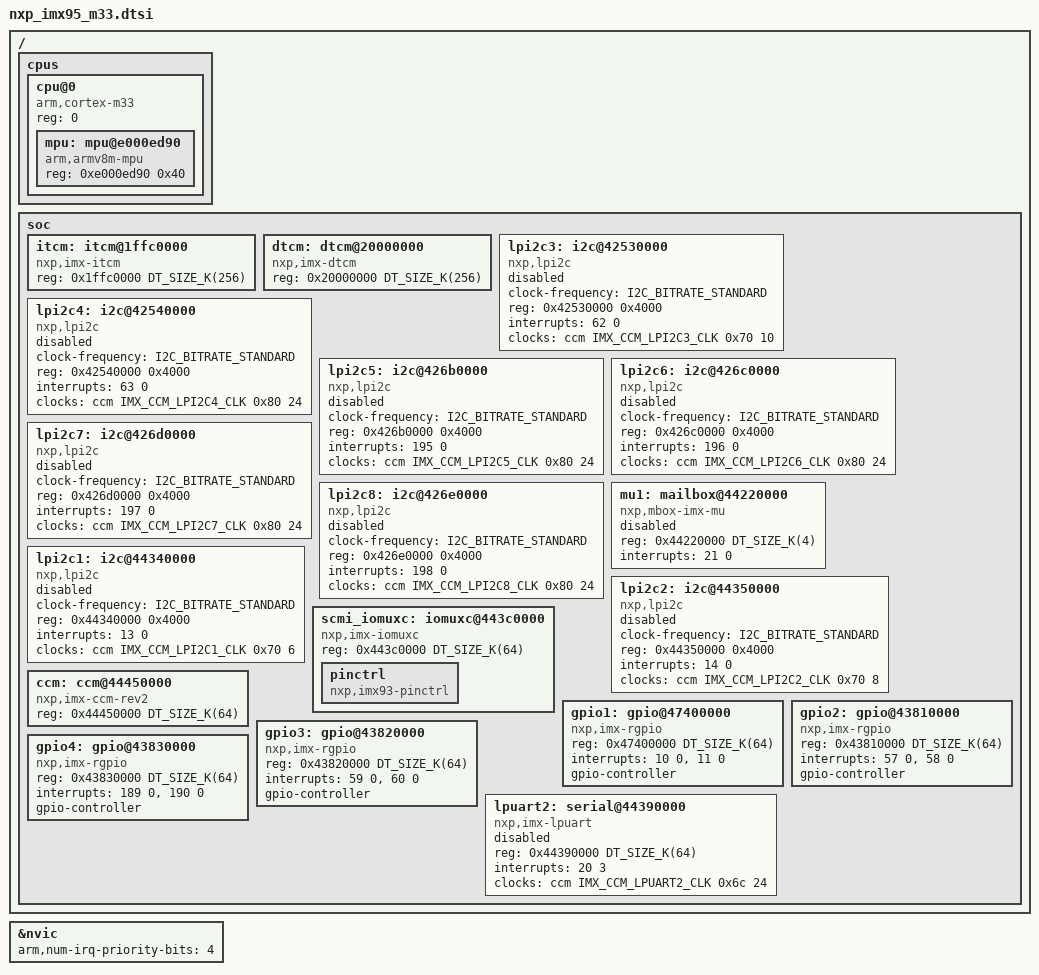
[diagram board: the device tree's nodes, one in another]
/*
 * SPDX-FileCopyrightText: Copyright 2024-2026 NXP
 * SPDX-License-Identifier: Apache-2.0
 */

#include <arm/armv8-m.dtsi>
#include <zephyr/dt-bindings/clock/imx_ccm_rev2.h>
#include <zephyr/dt-bindings/gpio/gpio.h>
#include <zephyr/dt-bindings/i2c/i2c.h>
#include <mem.h>
#include <freq.h>

/ {
	cpus {
		#address-cells = <1>;
		#size-cells = <0>;

		cpu@0 {
			device_type = "cpu";
			compatible = "arm,cortex-m33";
			reg = <0>;

			#address-cells = <1>;
			#size-cells = <1>;

			mpu: mpu@e000ed90 {
				compatible = "arm,armv8m-mpu";
				reg = <0xe000ed90 0x40>;
			};
		};
	};

	soc {
		itcm: itcm@1ffc0000 {
			compatible = "nxp,imx-itcm";
			reg = <0x1ffc0000 DT_SIZE_K(256)>;
		};

		dtcm: dtcm@20000000 {
			compatible = "nxp,imx-dtcm";
			reg = <0x20000000 DT_SIZE_K(256)>;
		};

		lpi2c3: i2c@42530000 {
			compatible = "nxp,lpi2c";
			clock-frequency = <I2C_BITRATE_STANDARD>;
			#address-cells = <1>;
			#size-cells = <0>;
			reg = <0x42530000 0x4000>;
			interrupts = <62 0>;
			clocks = <&ccm IMX_CCM_LPI2C3_CLK 0x70 10>;
			status = "disabled";
		};

		lpi2c4: i2c@42540000 {
			compatible = "nxp,lpi2c";
			clock-frequency = <I2C_BITRATE_STANDARD>;
			#address-cells = <1>;
			#size-cells = <0>;
			reg = <0x42540000 0x4000>;
			interrupts = <63 0>;
			clocks = <&ccm IMX_CCM_LPI2C4_CLK 0x80 24>;
			status = "disabled";
		};

		lpi2c5: i2c@426b0000 {
			compatible = "nxp,lpi2c";
			clock-frequency = <I2C_BITRATE_STANDARD>;
			#address-cells = <1>;
			#size-cells = <0>;
			reg = <0x426b0000 0x4000>;
			interrupts = <195 0>;
			clocks = <&ccm IMX_CCM_LPI2C5_CLK 0x80 24>;
			status = "disabled";
		};

		lpi2c6: i2c@426c0000 {
			compatible = "nxp,lpi2c";
			clock-frequency = <I2C_BITRATE_STANDARD>;
			#address-cells = <1>;
			#size-cells = <0>;
			reg = <0x426c0000 0x4000>;
			interrupts = <196 0>;
			clocks = <&ccm IMX_CCM_LPI2C6_CLK 0x80 24>;
			status = "disabled";
		};

		lpi2c7: i2c@426d0000 {
			compatible = "nxp,lpi2c";
			clock-frequency = <I2C_BITRATE_STANDARD>;
			#address-cells = <1>;
			#size-cells = <0>;
			reg = <0x426d0000 0x4000>;
			interrupts = <197 0>;
			clocks = <&ccm IMX_CCM_LPI2C7_CLK 0x80 24>;
			status = "disabled";
		};

		lpi2c8: i2c@426e0000 {
			compatible = "nxp,lpi2c";
			clock-frequency = <I2C_BITRATE_STANDARD>;
			#address-cells = <1>;
			#size-cells = <0>;
			reg = <0x426e0000 0x4000>;
			interrupts = <198 0>;
			clocks = <&ccm IMX_CCM_LPI2C8_CLK 0x80 24>;
			status = "disabled";
		};

		mu1: mailbox@44220000 {
			compatible = "nxp,mbox-imx-mu";
			reg = <0x44220000 DT_SIZE_K(4)>;
			interrupts = <21 0>;
			#mbox-cells = <1>;
			status = "disabled";
		};

		lpi2c1: i2c@44340000 {
			compatible = "nxp,lpi2c";
			clock-frequency = <I2C_BITRATE_STANDARD>;
			#address-cells = <1>;
			#size-cells = <0>;
			reg = <0x44340000 0x4000>;
			interrupts = <13 0>;
			clocks = <&ccm IMX_CCM_LPI2C1_CLK 0x70 6>;
			status = "disabled";
		};

		lpi2c2: i2c@44350000 {
			compatible = "nxp,lpi2c";
			clock-frequency = <I2C_BITRATE_STANDARD>;
			#address-cells = <1>;
			#size-cells = <0>;
			reg = <0x44350000 0x4000>;
			interrupts = <14 0>;
			clocks = <&ccm IMX_CCM_LPI2C2_CLK 0x70 8>;
			status = "disabled";
		};

		/*
		 * FIXME: need to name it this because of NXP dts
		 */
		scmi_iomuxc: iomuxc@443c0000 {
			compatible = "nxp,imx-iomuxc";
			reg = <0x443c0000 DT_SIZE_K(64)>;
			status = "okay";

			pinctrl: pinctrl {
				status = "okay";
				compatible = "nxp,imx93-pinctrl";
			};
		};

		ccm: ccm@44450000 {
			compatible = "nxp,imx-ccm-rev2";
			reg = <0x44450000 DT_SIZE_K(64)>;
			#clock-cells = <3>;
		};

		gpio1: gpio@47400000 {
			compatible = "nxp,imx-rgpio";
			reg = <0x47400000 DT_SIZE_K(64)>;
			interrupts = <10 0>, <11 0>;
			gpio-controller;
			#gpio-cells = <2>;
		};

		gpio2: gpio@43810000 {
			compatible = "nxp,imx-rgpio";
			reg = <0x43810000 DT_SIZE_K(64)>;
			interrupts = <57 0>, <58 0>;
			gpio-controller;
			#gpio-cells = <2>;
		};

		gpio3: gpio@43820000 {
			compatible = "nxp,imx-rgpio";
			reg = <0x43820000 DT_SIZE_K(64)>;
			interrupts = <59 0>, <60 0>;
			gpio-controller;
			#gpio-cells = <2>;
		};

		gpio4: gpio@43830000 {
			compatible = "nxp,imx-rgpio";
			reg = <0x43830000 DT_SIZE_K(64)>;
			interrupts = <189 0>, <190 0>;
			gpio-controller;
			#gpio-cells = <2>;
		};

		lpuart2: serial@44390000 {
			compatible = "nxp,imx-lpuart", "nxp,lpuart";
			reg = <0x44390000 DT_SIZE_K(64)>;
			interrupts = <20 3>;
			clocks = <&ccm IMX_CCM_LPUART2_CLK 0x6c 24>;
			status = "disabled";
		};
	};
};

&nvic {
	arm,num-irq-priority-bits = <4>;
};
